# ESP32-P4 register map
Vendor: ESPRESSIF SYSTEMS (SHANGHAI) CO., LTD.; Series: ESP32 P-Series; File version: 3
CPU: RV32IMAFC r0p0, little endian, no MPU, FPU, 0 interrupt priority bits
Address unit: 32 bits
Registers are 32-bit, read-write, reset 0x0 unless marked. A register's access mark holds for its fields unless they carry their own. Offsets are from the block's base; [hi:lo] are bit positions; {n}, {i} and the like mark numbered series.

## LP_I2C_ANA_MST — LP_I2C_ANA_MST Peripheral
Base 0x50124000
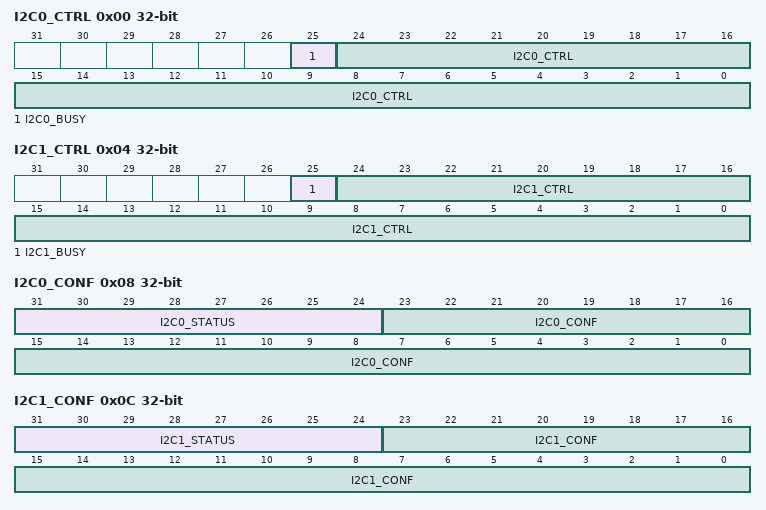
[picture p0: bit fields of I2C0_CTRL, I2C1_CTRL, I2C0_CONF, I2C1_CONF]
0x00 I2C0_CTRL access per field — need des
  [25] I2C0_BUSY ro — need des
  [24:0] I2C0_CTRL rw — need des
0x04 I2C1_CTRL access per field — need des
  [25] I2C1_BUSY ro — need des
  [24:0] I2C1_CTRL rw — need des
0x08 I2C0_CONF access per field — need des
  [31:24] I2C0_STATUS ro — need des
  [23:0] I2C0_CONF rw — need des
0x0C I2C1_CONF access per field — need des
  [31:24] I2C1_STATUS ro — need des
  [23:0] I2C1_CONF rw — need des
0x10 I2C_BURST_CONF — need des
  [31:0] I2C_MST_BURST_CTRL
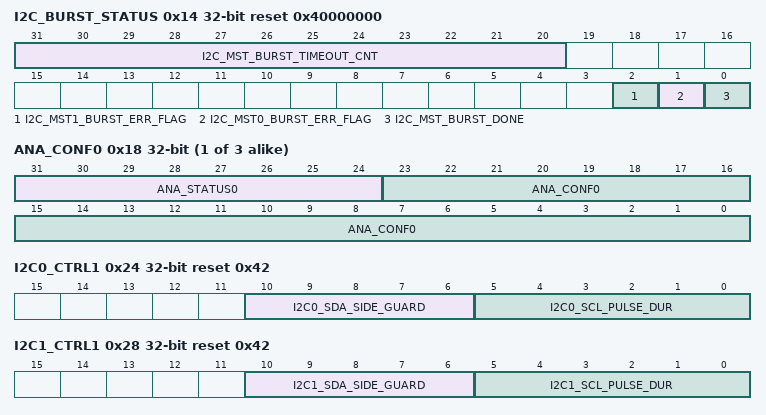
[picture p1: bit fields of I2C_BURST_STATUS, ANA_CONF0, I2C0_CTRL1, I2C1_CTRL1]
0x14 I2C_BURST_STATUS access per field reset 0x40000000 — need des
  [31:20] I2C_MST_BURST_TIMEOUT_CNT rw — need des
  [2] I2C_MST1_BURST_ERR_FLAG ro — need des
  [1] I2C_MST0_BURST_ERR_FLAG ro — need des
  [0] I2C_MST_BURST_DONE ro — need des
{0x18+4i} ANA_CONF{i} access per field (i=0..2) — need des
  [31:24] ANA_STATUS{i} ro — need des
  [23:0] ANA_CONF{i} rw — need des
0x24 I2C0_CTRL1 reset 0x42 — need des
  [10:6] I2C0_SDA_SIDE_GUARD — need des
  [5:0] I2C0_SCL_PULSE_DUR — need des
0x28 I2C1_CTRL1 reset 0x42 — need des
  [10:6] I2C1_SDA_SIDE_GUARD — need des
  [5:0] I2C1_SCL_PULSE_DUR — need des
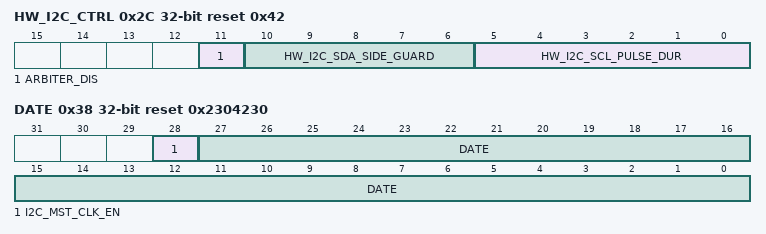
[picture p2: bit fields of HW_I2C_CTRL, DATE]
0x2C HW_I2C_CTRL reset 0x42 — need des
  [11] ARBITER_DIS — need des
  [10:6] HW_I2C_SDA_SIDE_GUARD — need des
  [5:0] HW_I2C_SCL_PULSE_DUR — need des
0x30 NOUSE — need des
  [31:0] I2C_MST_NOUSE
0x34 CLK160M — need des
  [0] CLK_I2C_MST_SEL_160M
0x38 DATE reset 0x2304230 — need des
  [28] I2C_MST_CLK_EN — need des
  [27:0] DATE — need des

## MIPI_CSI_HOST — MIPI Camera Interface Host
Base 0x5009F000
0x00 VERSION ro reset 0x3135302A
0x04 N_LANES reset 0x1
  [2:0] N_LANES
0x08 CSI2_RESETN
  [0] CSI2_RESETN
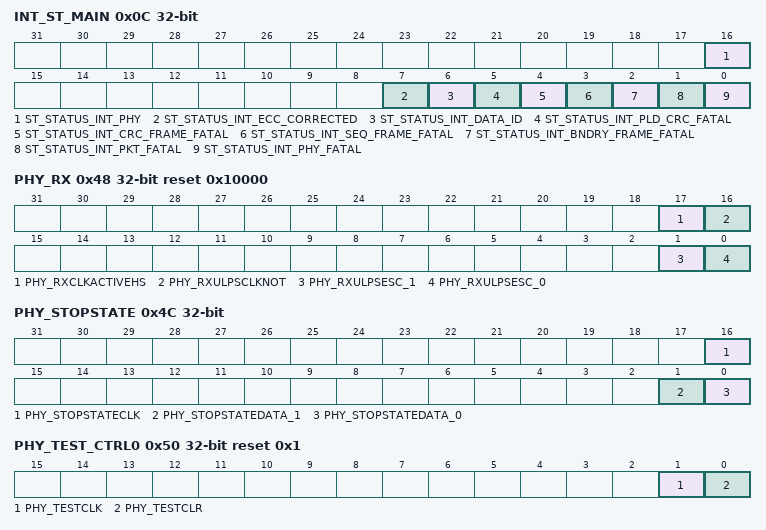
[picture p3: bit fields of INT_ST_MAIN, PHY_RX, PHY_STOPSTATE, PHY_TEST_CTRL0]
0x0C INT_ST_MAIN ro
  [16] ST_STATUS_INT_PHY, [7] ST_STATUS_INT_ECC_CORRECTED, [6] ST_STATUS_INT_DATA_ID, [5] ST_STATUS_INT_PLD_CRC_FATAL, [4] ST_STATUS_INT_CRC_FRAME_FATAL, [3] ST_STATUS_INT_SEQ_FRAME_FATAL, [2] ST_STATUS_INT_BNDRY_FRAME_FATAL, [1] ST_STATUS_INT_PKT_FATAL, [0] ST_STATUS_INT_PHY_FATAL
0x40 PHY_SHUTDOWNZ
  [0] PHY_SHUTDOWNZ
0x44 DPHY_RSTZ
  [0] DPHY_RSTZ
0x48 PHY_RX ro reset 0x10000
  [17] PHY_RXCLKACTIVEHS, [16] PHY_RXULPSCLKNOT, [1] PHY_RXULPSESC_1, [0] PHY_RXULPSESC_0
0x4C PHY_STOPSTATE ro
  [16] PHY_STOPSTATECLK, [1] PHY_STOPSTATEDATA_1, [0] PHY_STOPSTATEDATA_0
0x50 PHY_TEST_CTRL0 reset 0x1
  [1] PHY_TESTCLK, [0] PHY_TESTCLR
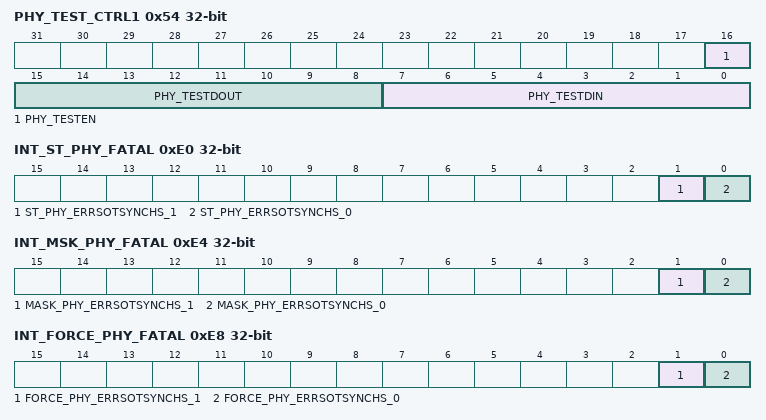
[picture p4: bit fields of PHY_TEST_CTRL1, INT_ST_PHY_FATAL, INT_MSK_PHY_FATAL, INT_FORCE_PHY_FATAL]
0x54 PHY_TEST_CTRL1 access per field
  [16] PHY_TESTEN rw, [15:8] PHY_TESTDOUT ro, [7:0] PHY_TESTDIN rw
0xC8 VC_EXTENSION
  [0] VCX
0xCC PHY_CAL ro
  [0] RXSKEWCALHS
0xE0 INT_ST_PHY_FATAL ro
  [1] ST_PHY_ERRSOTSYNCHS_1, [0] ST_PHY_ERRSOTSYNCHS_0
0xE4 INT_MSK_PHY_FATAL
  [1] MASK_PHY_ERRSOTSYNCHS_1, [0] MASK_PHY_ERRSOTSYNCHS_0
0xE8 INT_FORCE_PHY_FATAL
  [1] FORCE_PHY_ERRSOTSYNCHS_1, [0] FORCE_PHY_ERRSOTSYNCHS_0
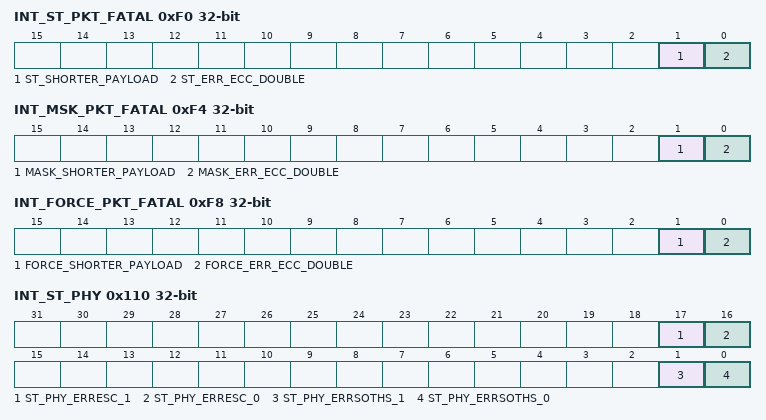
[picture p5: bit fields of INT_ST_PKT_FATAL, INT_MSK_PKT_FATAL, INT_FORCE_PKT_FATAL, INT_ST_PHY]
0xF0 INT_ST_PKT_FATAL ro
  [1] ST_SHORTER_PAYLOAD, [0] ST_ERR_ECC_DOUBLE
0xF4 INT_MSK_PKT_FATAL
  [1] MASK_SHORTER_PAYLOAD, [0] MASK_ERR_ECC_DOUBLE
0xF8 INT_FORCE_PKT_FATAL
  [1] FORCE_SHORTER_PAYLOAD, [0] FORCE_ERR_ECC_DOUBLE
0x110 INT_ST_PHY ro
  [17] ST_PHY_ERRESC_1, [16] ST_PHY_ERRESC_0, [1] ST_PHY_ERRSOTHS_1, [0] ST_PHY_ERRSOTHS_0
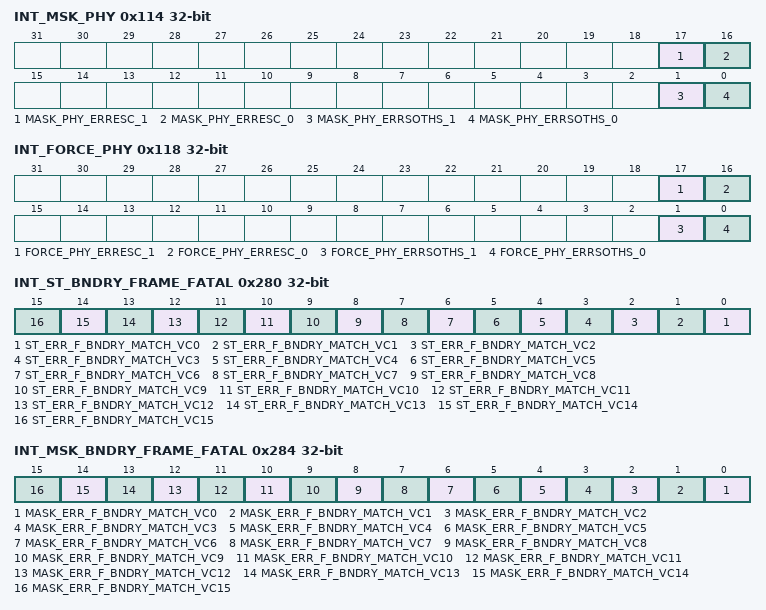
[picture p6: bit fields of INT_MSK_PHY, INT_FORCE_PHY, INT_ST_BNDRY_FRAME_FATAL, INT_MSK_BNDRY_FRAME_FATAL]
0x114 INT_MSK_PHY
  [17] MASK_PHY_ERRESC_1, [16] MASK_PHY_ERRESC_0, [1] MASK_PHY_ERRSOTHS_1, [0] MASK_PHY_ERRSOTHS_0
0x118 INT_FORCE_PHY
  [17] FORCE_PHY_ERRESC_1, [16] FORCE_PHY_ERRESC_0, [1] FORCE_PHY_ERRSOTHS_1, [0] FORCE_PHY_ERRSOTHS_0
0x280 INT_ST_BNDRY_FRAME_FATAL ro
  [n] ST_ERR_F_BNDRY_MATCH_VC{n} (n=0..15)
0x284 INT_MSK_BNDRY_FRAME_FATAL
  [n] MASK_ERR_F_BNDRY_MATCH_VC{n} (n=0..15)
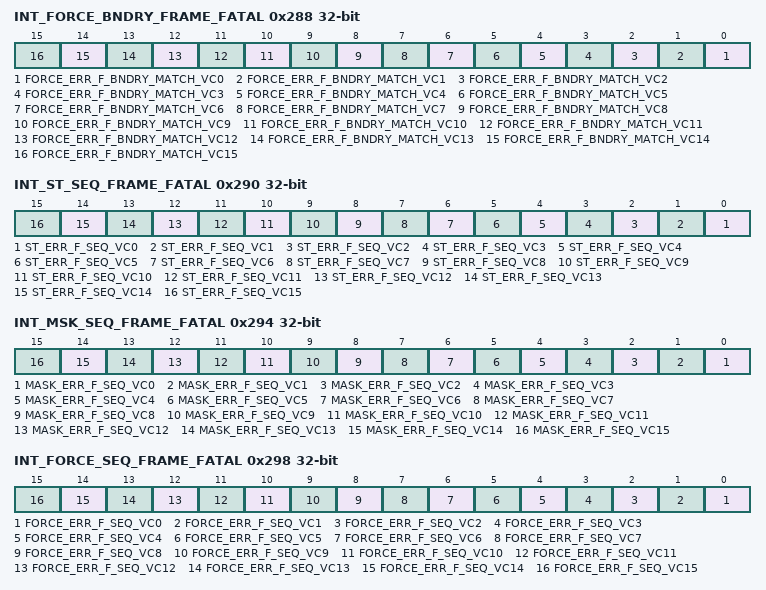
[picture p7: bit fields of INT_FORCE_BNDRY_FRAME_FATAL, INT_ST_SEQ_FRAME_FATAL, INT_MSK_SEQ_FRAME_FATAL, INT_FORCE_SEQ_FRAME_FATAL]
0x288 INT_FORCE_BNDRY_FRAME_FATAL
  [n] FORCE_ERR_F_BNDRY_MATCH_VC{n} (n=0..15)
0x290 INT_ST_SEQ_FRAME_FATAL ro
  [n] ST_ERR_F_SEQ_VC{n} (n=0..15)
0x294 INT_MSK_SEQ_FRAME_FATAL
  [n] MASK_ERR_F_SEQ_VC{n} (n=0..15)
0x298 INT_FORCE_SEQ_FRAME_FATAL
  [n] FORCE_ERR_F_SEQ_VC{n} (n=0..15)
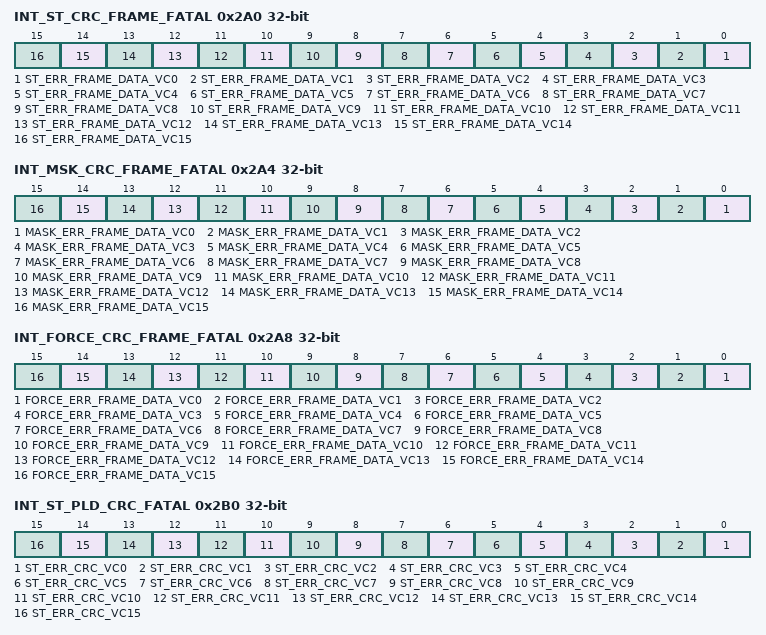
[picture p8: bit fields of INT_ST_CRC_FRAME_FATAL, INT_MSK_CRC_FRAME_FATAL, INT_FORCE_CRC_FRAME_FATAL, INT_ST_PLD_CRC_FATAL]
0x2A0 INT_ST_CRC_FRAME_FATAL ro
  [n] ST_ERR_FRAME_DATA_VC{n} (n=0..15)
0x2A4 INT_MSK_CRC_FRAME_FATAL
  [n] MASK_ERR_FRAME_DATA_VC{n} (n=0..15)
0x2A8 INT_FORCE_CRC_FRAME_FATAL
  [n] FORCE_ERR_FRAME_DATA_VC{n} (n=0..15)
0x2B0 INT_ST_PLD_CRC_FATAL ro
  [n] ST_ERR_CRC_VC{n} (n=0..15)
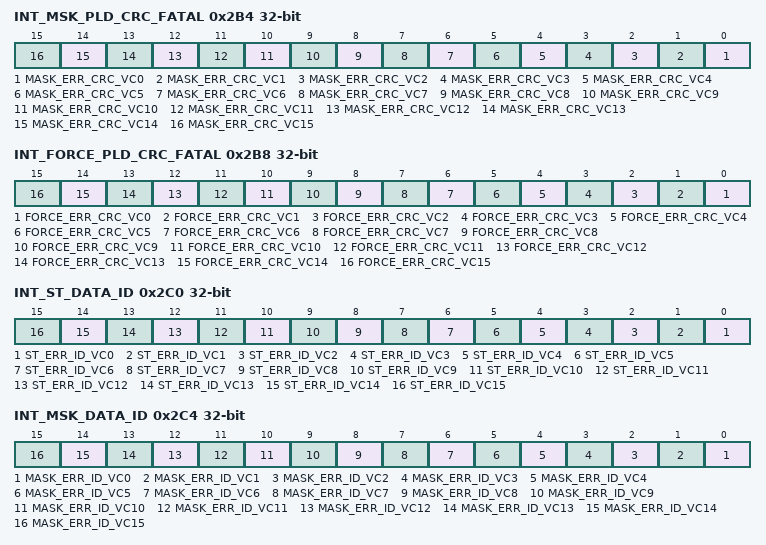
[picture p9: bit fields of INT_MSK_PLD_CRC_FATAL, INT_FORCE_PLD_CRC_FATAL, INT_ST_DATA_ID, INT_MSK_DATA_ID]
0x2B4 INT_MSK_PLD_CRC_FATAL
  [n] MASK_ERR_CRC_VC{n} (n=0..15)
0x2B8 INT_FORCE_PLD_CRC_FATAL
  [n] FORCE_ERR_CRC_VC{n} (n=0..15)
0x2C0 INT_ST_DATA_ID ro
  [n] ST_ERR_ID_VC{n} (n=0..15)
0x2C4 INT_MSK_DATA_ID
  [n] MASK_ERR_ID_VC{n} (n=0..15)
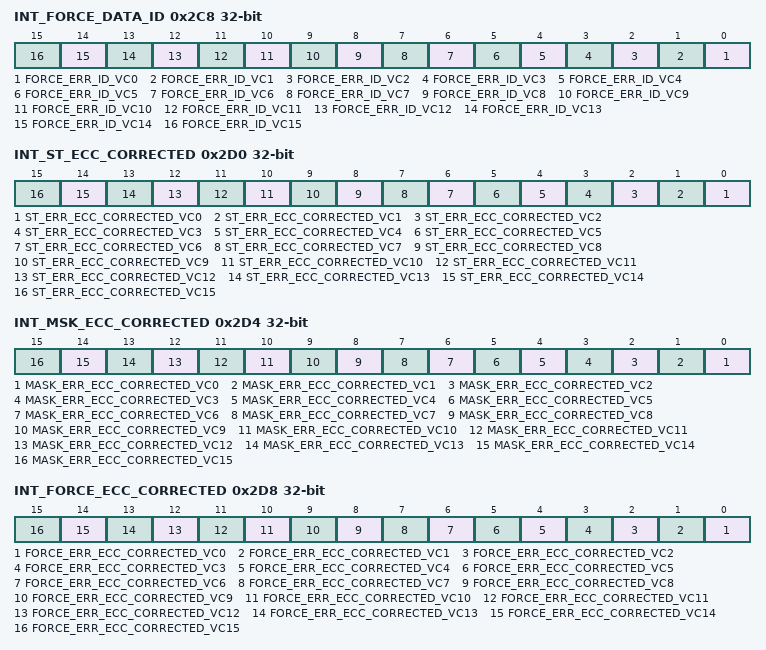
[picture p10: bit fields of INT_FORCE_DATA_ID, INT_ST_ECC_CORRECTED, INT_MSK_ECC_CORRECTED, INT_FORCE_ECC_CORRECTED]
0x2C8 INT_FORCE_DATA_ID
  [n] FORCE_ERR_ID_VC{n} (n=0..15)
0x2D0 INT_ST_ECC_CORRECTED ro
  [n] ST_ERR_ECC_CORRECTED_VC{n} (n=0..15)
0x2D4 INT_MSK_ECC_CORRECTED
  [n] MASK_ERR_ECC_CORRECTED_VC{n} (n=0..15)
0x2D8 INT_FORCE_ECC_CORRECTED
  [n] FORCE_ERR_ECC_CORRECTED_VC{n} (n=0..15)
0x300 SCRAMBLING
  [0] SCRAMBLE_ENABLE
0x304 SCRAMBLING_SEED1 reset 0x1008
  [15:0] SCRAMBLE_SEED_LANE1
0x308 SCRAMBLING_SEED2 reset 0x1188
  [15:0] SCRAMBLE_SEED_LANE2
